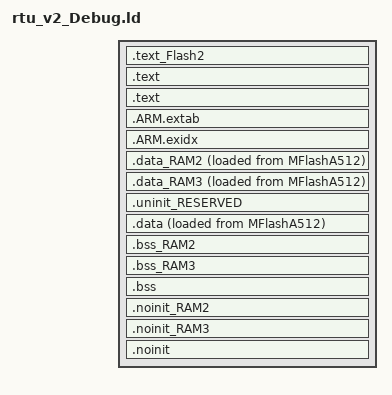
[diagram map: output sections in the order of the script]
/*
 * GENERATED FILE - DO NOT EDIT
 * Copyright (c) 2008-2013 Code Red Technologies Ltd,
 * Copyright 2015, 2018-2019 NXP
 * (c) NXP Semiconductors 2013-2022
 * Generated linker script file for LPC4337
 * Created from linkscript.ldt by FMCreateLinkLibraries
 * Using Freemarker v2.3.30
 * MCUXpresso IDE v11.3.0 [Build 5222] [2021-01-11] on 07/12/2022 14:59:23
 */

INCLUDE "rtu_v2_Debug_library.ld"
INCLUDE "rtu_v2_Debug_memory.ld"

ENTRY(ResetISR)

SECTIONS
{
     .text_Flash2 : ALIGN(4)
    {
       FILL(0xff)
        *(.text_Flash2) /* for compatibility with previous releases */
        *(.text_MFlashB512) /* for compatibility with previous releases */
        *(.text.$Flash2)
        *(.text.$MFlashB512)
        *(.text_Flash2.*) /* for compatibility with previous releases */
        *(.text_MFlashB512.*) /* for compatibility with previous releases */
        *(.text.$Flash2.*)
        *(.text.$MFlashB512.*)
        *(.rodata.$Flash2)
        *(.rodata.$MFlashB512)
        *(.rodata.$Flash2.*)
        *(.rodata.$MFlashB512.*)            } > MFlashB512

    /* MAIN TEXT SECTION */
    .text : ALIGN(4)
    {
        FILL(0xff)
        __vectors_start__ = ABSOLUTE(.) ;
        KEEP(*(.isr_vector))
        /* Global Section Table */
        . = ALIGN(4) ;
        __section_table_start = .;
        __data_section_table = .;
        LONG(LOADADDR(.data));
        LONG(    ADDR(.data));
        LONG(  SIZEOF(.data));
        LONG(LOADADDR(.data_RAM2));
        LONG(    ADDR(.data_RAM2));
        LONG(  SIZEOF(.data_RAM2));
        LONG(LOADADDR(.data_RAM3));
        LONG(    ADDR(.data_RAM3));
        LONG(  SIZEOF(.data_RAM3));
        __data_section_table_end = .;
        __bss_section_table = .;
        LONG(    ADDR(.bss));
        LONG(  SIZEOF(.bss));
        LONG(    ADDR(.bss_RAM2));
        LONG(  SIZEOF(.bss_RAM2));
        LONG(    ADDR(.bss_RAM3));
        LONG(  SIZEOF(.bss_RAM3));
        __bss_section_table_end = .;
        __section_table_end = . ;
        /* End of Global Section Table */

        *(.after_vectors*)

        /* Code Read Protection data */
        . = 0x000002FC ;
        PROVIDE(__CRP_WORD_START__ = .) ;
        KEEP(*(.crp))
        PROVIDE(__CRP_WORD_END__ = .) ;
        ASSERT(!(__CRP_WORD_START__ == __CRP_WORD_END__), "Linker CRP Enabled, but no CRP_WORD provided within application");
        /* End of Code Read Protection */
    } > MFlashA512

    .text : ALIGN(4)
    {
       *(.text*)
       *(.rodata .rodata.* .constdata .constdata.*)
       . = ALIGN(4);
    } > MFlashA512
    /*
     * for exception handling/unwind - some Newlib functions (in common
     * with C++ and STDC++) use this.
     */
    .ARM.extab : ALIGN(4)
    {
        *(.ARM.extab* .gnu.linkonce.armextab.*)
    } > MFlashA512

    .ARM.exidx : ALIGN(4)
    {
        __exidx_start = .;
        *(.ARM.exidx* .gnu.linkonce.armexidx.*)
        __exidx_end = .;
    } > MFlashA512
 
    _etext = .;
        
    /* DATA section for RamLoc40 */

    .data_RAM2 : ALIGN(4)
    {
        FILL(0xff)
        PROVIDE(__start_data_RAM2 = .) ;
        PROVIDE(__start_data_RamLoc40 = .) ;
        *(.ramfunc.$RAM2)
        *(.ramfunc.$RamLoc40)
        *(.data.$RAM2)
        *(.data.$RamLoc40)
        *(.data.$RAM2.*)
        *(.data.$RamLoc40.*)
        . = ALIGN(4) ;
        PROVIDE(__end_data_RAM2 = .) ;
        PROVIDE(__end_data_RamLoc40 = .) ;
     } > RamLoc40 AT>MFlashA512

    /* DATA section for RamAHB32_48_64 */

    .data_RAM3 : ALIGN(4)
    {
        FILL(0xff)
        PROVIDE(__start_data_RAM3 = .) ;
        PROVIDE(__start_data_RamAHB32_48_64 = .) ;
        *(.ramfunc.$RAM3)
        *(.ramfunc.$RamAHB32_48_64)
        *(.data.$RAM3)
        *(.data.$RamAHB32_48_64)
        *(.data.$RAM3.*)
        *(.data.$RamAHB32_48_64.*)
        . = ALIGN(4) ;
        PROVIDE(__end_data_RAM3 = .) ;
        PROVIDE(__end_data_RamAHB32_48_64 = .) ;
     } > RamAHB32_48_64 AT>MFlashA512

    /* MAIN DATA SECTION */
    .uninit_RESERVED (NOLOAD) : ALIGN(4)
    {
        _start_uninit_RESERVED = .;
        KEEP(*(.bss.$RESERVED*))
       . = ALIGN(4) ;
        _end_uninit_RESERVED = .;
    } > RamLoc32 AT> RamLoc32

    /* Main DATA section (RamLoc32) */
    .data : ALIGN(4)
    {
       FILL(0xff)
       _data = . ;
       PROVIDE(__start_data_RAM = .) ;
       PROVIDE(__start_data_RamLoc32 = .) ;
       *(vtable)
       *(.ramfunc*)
       KEEP(*(CodeQuickAccess))
       KEEP(*(DataQuickAccess))
       *(RamFunction)
       *(.data*)
       . = ALIGN(4) ;
       _edata = . ;
       PROVIDE(__end_data_RAM = .) ;
       PROVIDE(__end_data_RamLoc32 = .) ;
    } > RamLoc32 AT>MFlashA512

    /* BSS section for RamLoc40 */
    .bss_RAM2 : ALIGN(4)
    {
       PROVIDE(__start_bss_RAM2 = .) ;
       PROVIDE(__start_bss_RamLoc40 = .) ;
       *(.bss.$RAM2)
       *(.bss.$RamLoc40)
       *(.bss.$RAM2.*)
       *(.bss.$RamLoc40.*)
       . = ALIGN (. != 0 ? 4 : 1) ; /* avoid empty segment */
       PROVIDE(__end_bss_RAM2 = .) ;
       PROVIDE(__end_bss_RamLoc40 = .) ;
    } > RamLoc40 AT> RamLoc40

    /* BSS section for RamAHB32_48_64 */
    .bss_RAM3 : ALIGN(4)
    {
       PROVIDE(__start_bss_RAM3 = .) ;
       PROVIDE(__start_bss_RamAHB32_48_64 = .) ;
       *(.bss.$RAM3)
       *(.bss.$RamAHB32_48_64)
       *(.bss.$RAM3.*)
       *(.bss.$RamAHB32_48_64.*)
       . = ALIGN (. != 0 ? 4 : 1) ; /* avoid empty segment */
       PROVIDE(__end_bss_RAM3 = .) ;
       PROVIDE(__end_bss_RamAHB32_48_64 = .) ;
    } > RamAHB32_48_64 AT> RamAHB32_48_64

    /* MAIN BSS SECTION */
    .bss : ALIGN(4)
    {
        _bss = .;
        PROVIDE(__start_bss_RAM = .) ;
        PROVIDE(__start_bss_RamLoc32 = .) ;
        *(.bss*)
        *(COMMON)
        . = ALIGN(4) ;
        _ebss = .;
        PROVIDE(__end_bss_RAM = .) ;
        PROVIDE(__end_bss_RamLoc32 = .) ;
        PROVIDE(end = .);
    } > RamLoc32 AT> RamLoc32

    /* NOINIT section for RamLoc40 */
    .noinit_RAM2 (NOLOAD) : ALIGN(4)
    {
       PROVIDE(__start_noinit_RAM2 = .) ;
       PROVIDE(__start_noinit_RamLoc40 = .) ;
       *(.noinit.$RAM2)
       *(.noinit.$RamLoc40)
       *(.noinit.$RAM2.*)
       *(.noinit.$RamLoc40.*)
       . = ALIGN(4) ;
       PROVIDE(__end_noinit_RAM2 = .) ;
       PROVIDE(__end_noinit_RamLoc40 = .) ;
    } > RamLoc40 AT> RamLoc40

    /* NOINIT section for RamAHB32_48_64 */
    .noinit_RAM3 (NOLOAD) : ALIGN(4)
    {
       PROVIDE(__start_noinit_RAM3 = .) ;
       PROVIDE(__start_noinit_RamAHB32_48_64 = .) ;
       *(.noinit.$RAM3)
       *(.noinit.$RamAHB32_48_64)
       *(.noinit.$RAM3.*)
       *(.noinit.$RamAHB32_48_64.*)
       . = ALIGN(4) ;
       PROVIDE(__end_noinit_RAM3 = .) ;
       PROVIDE(__end_noinit_RamAHB32_48_64 = .) ;
    } > RamAHB32_48_64 AT> RamAHB32_48_64

    /* DEFAULT NOINIT SECTION */
    .noinit (NOLOAD): ALIGN(4)
    {
        _noinit = .;
        PROVIDE(__start_noinit_RAM = .) ;
        PROVIDE(__start_noinit_RamLoc32 = .) ;
        *(.noinit*)
         . = ALIGN(4) ;
        _end_noinit = .;
       PROVIDE(__end_noinit_RAM = .) ;
       PROVIDE(__end_noinit_RamLoc32 = .) ;        
    } > RamLoc32 AT> RamLoc32
    PROVIDE(_pvHeapStart = DEFINED(__user_heap_base) ? __user_heap_base : .);
    PROVIDE(_vStackTop = DEFINED(__user_stack_top) ? __user_stack_top : __top_RamLoc32 - 0);

    /* ## Create checksum value (used in startup) ## */
    PROVIDE(__valid_user_code_checksum = 0 - 
                                         (_vStackTop 
                                         + (ResetISR + 1) 
                                         + (NMI_Handler + 1) 
                                         + (HardFault_Handler + 1) 
                                         + (( DEFINED(MemManage_Handler) ? MemManage_Handler : 0 ) + 1)   /* MemManage_Handler may not be defined */
                                         + (( DEFINED(BusFault_Handler) ? BusFault_Handler : 0 ) + 1)     /* BusFault_Handler may not be defined */
                                         + (( DEFINED(UsageFault_Handler) ? UsageFault_Handler : 0 ) + 1) /* UsageFault_Handler may not be defined */
                                         ) );

    /* Provide basic symbols giving location and size of main text
     * block, including initial values of RW data sections. Note that
     * these will need extending to give a complete picture with
     * complex images (e.g multiple Flash banks).
     */
    _image_start = LOADADDR(.text);
    _image_end = LOADADDR(.data) + SIZEOF(.data);
    _image_size = _image_end - _image_start;
}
